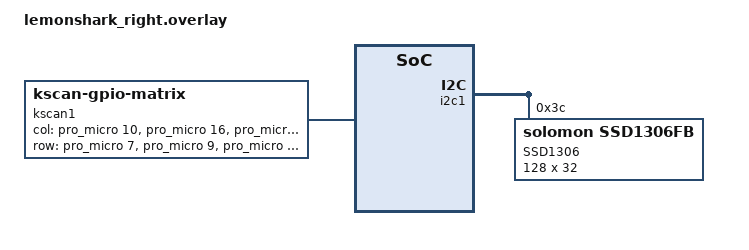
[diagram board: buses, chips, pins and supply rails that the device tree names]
#include "lemonshark.dtsi"

/ {
    kscan1: kscan1 {
        compatible = "zmk,kscan-gpio-matrix";
        diode-direction = "col2row";
        wakeup-source;

        col-gpios
            = <&pro_micro 10 GPIO_ACTIVE_HIGH>,
              <&pro_micro 16 GPIO_ACTIVE_HIGH>,
              <&pro_micro 14 GPIO_ACTIVE_HIGH>,
              <&pro_micro 15 GPIO_ACTIVE_HIGH>,
              <&pro_micro 18 GPIO_ACTIVE_HIGH>,
              <&pro_micro 19 GPIO_ACTIVE_HIGH>,
              <&pro_micro 20 GPIO_ACTIVE_HIGH>;

        row-gpios
            = <&pro_micro 7 (GPIO_ACTIVE_HIGH | GPIO_PULL_DOWN)>,
              <&pro_micro 9 (GPIO_ACTIVE_HIGH | GPIO_PULL_DOWN)>,
              <&pro_micro 6 (GPIO_ACTIVE_HIGH | GPIO_PULL_DOWN)>,
              <&pro_micro 8 (GPIO_ACTIVE_HIGH | GPIO_PULL_DOWN)>;
    };
};

/* Right side matrix transform offset */
&matrix_transform0 {
    col-offset = <7>;
};

/* Right half uses its own kscan */
&physical_layout_lemonshark {
    kscan = <&kscan1>;
};


&i2c1 {
    status = "okay";

    ssd1306: ssd1306@3c {
        compatible = "solomon,ssd1306fb";
        reg = <0x3c>;

        label = "SSD1306";

        width = <128>;
        height = <32>;

        segment-offset = <0>;
        page-offset = <0>;
        display-offset = <0>;

        multiplex-ratio = <31>;

        segment-remap;
        com-invdir;

        prechargep = <0x22>;
    };
};

/ {
    chosen {
        zephyr,display = &ssd1306;
    };
};
